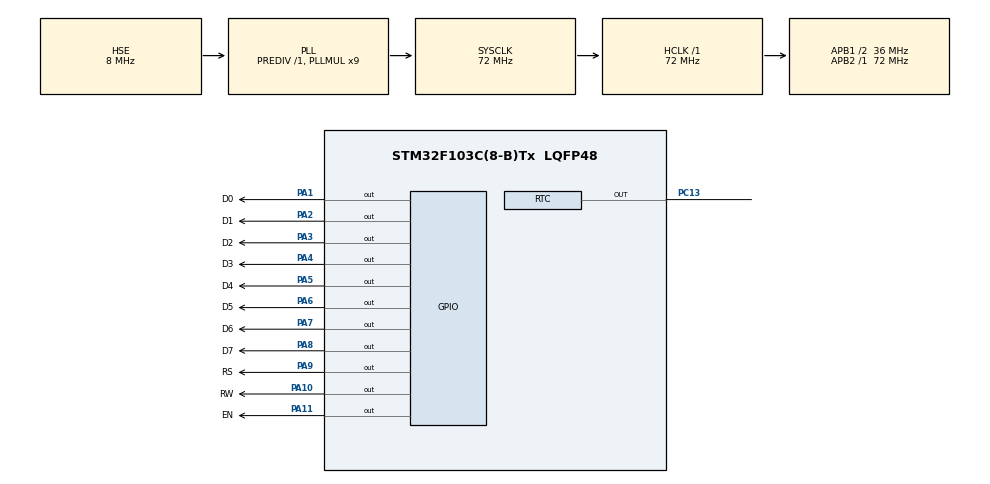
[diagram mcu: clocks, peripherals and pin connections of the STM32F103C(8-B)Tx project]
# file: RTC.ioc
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Mcu.Family=STM32F1
Mcu.Name=STM32F103C(8-B)Tx
Mcu.Package=LQFP48
NVIC.PriorityGroup=NVIC_PRIORITYGROUP_4
PA1.GPIO_Label=D0
PA1.GPIO_ModeDefaultOutputPP=GPIO_MODE_OUTPUT_PP
PA1.GPIO_Speed=GPIO_SPEED_FREQ_LOW
PA1.Signal=GPIO_Output
PA10.GPIO_Label=RW
PA10.GPIO_ModeDefaultOutputPP=GPIO_MODE_OUTPUT_PP
PA10.GPIO_Speed=GPIO_SPEED_FREQ_LOW
PA10.Signal=GPIO_Output
PA11.GPIO_Label=EN
PA11.GPIO_ModeDefaultOutputPP=GPIO_MODE_OUTPUT_PP
PA11.GPIO_Speed=GPIO_SPEED_FREQ_LOW
PA11.Signal=GPIO_Output
PA13.Signal=SYS_JTMS-SWDIO
PA14.Signal=SYS_JTCK-SWCLK
PA2.GPIO_Label=D1
PA2.GPIO_ModeDefaultOutputPP=GPIO_MODE_OUTPUT_PP
PA2.GPIO_Speed=GPIO_SPEED_FREQ_LOW
PA2.Signal=GPIO_Output
PA3.GPIO_Label=D2
PA3.GPIO_ModeDefaultOutputPP=GPIO_MODE_OUTPUT_PP
PA3.GPIO_Speed=GPIO_SPEED_FREQ_LOW
PA3.Signal=GPIO_Output
PA4.GPIO_Label=D3
PA4.GPIO_ModeDefaultOutputPP=GPIO_MODE_OUTPUT_PP
PA4.GPIO_Speed=GPIO_SPEED_FREQ_LOW
PA4.Signal=GPIO_Output
PA5.GPIO_Label=D4
PA5.GPIO_ModeDefaultOutputPP=GPIO_MODE_OUTPUT_PP
PA5.GPIO_Speed=GPIO_SPEED_FREQ_LOW
PA5.Signal=GPIO_Output
PA6.GPIO_Label=D5
PA6.GPIO_ModeDefaultOutputPP=GPIO_MODE_OUTPUT_PP
PA6.GPIO_Speed=GPIO_SPEED_FREQ_LOW
PA6.Signal=GPIO_Output
PA7.GPIO_Label=D6
PA7.GPIO_ModeDefaultOutputPP=GPIO_MODE_OUTPUT_PP
PA7.GPIO_Speed=GPIO_SPEED_FREQ_LOW
PA7.Signal=GPIO_Output
PA8.GPIO_Label=D7
PA8.GPIO_ModeDefaultOutputPP=GPIO_MODE_OUTPUT_PP
PA8.GPIO_Speed=GPIO_SPEED_FREQ_LOW
PA8.Signal=GPIO_Output
PA9.GPIO_Label=RS
PA9.GPIO_ModeDefaultOutputPP=GPIO_MODE_OUTPUT_PP
PA9.GPIO_Speed=GPIO_SPEED_FREQ_LOW
PA9.Signal=GPIO_Output
PC13-TAMPER-RTC.Mode=RTC OUT
PC13-TAMPER-RTC.Signal=RTC_OUT
PD0-OSC_IN.Mode=HSE-External-Oscillator
PD0-OSC_IN.Signal=RCC_OSC_IN
PD1-OSC_OUT.Mode=HSE-External-Oscillator
PD1-OSC_OUT.Signal=RCC_OSC_OUT
ProjectManager.HeapSize=0x200
ProjectManager.StackSize=0x400
ProjectManager.TargetToolchain=MDK-ARM V5
RCC.AHBFreq_Value=72000000
RCC.APB1CLKDivider=RCC_HCLK_DIV2
RCC.APB1Freq_Value=36000000
RCC.APB1TimFreq_Value=72000000
RCC.APB2Freq_Value=72000000
RCC.APB2TimFreq_Value=72000000
RCC.EnbaleCSS=true
RCC.HCLKFreq_Value=72000000
RCC.PLLMUL=RCC_PLL_MUL9
RCC.PLLSourceVirtual=RCC_PLLSOURCE_HSE
RCC.SYSCLKFreq_VALUE=72000000
RCC.SYSCLKSource=RCC_SYSCLKSOURCE_PLLCLK
RCC.USBFreq_Value=72000000
RTC.Date=21
RTC.Hours=2
RTC.Month=RTC_MONTH_SEPTEMBER
RTC.OutPut=RTC_OUTPUTSOURCE_SECOND
RTC.Year=20
VP_RTC_VS_RTC_Activate.Mode=RTC_Enabled
VP_RTC_VS_RTC_Calendar.Mode=RTC_Calendar
VP_SYS_VS_ND.Mode=No_Debug
board=custom

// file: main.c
/* USER CODE BEGIN Header */
/**
  ******************************************************************************
  * @file           : main.c
  * @brief          : Main program body
  ******************************************************************************
  * @attention
  *
  * <h2><center>&copy; Copyright (c) 2020 STMicroelectronics.
  * All rights reserved.</center></h2>
  *
  * This software component is licensed by ST under BSD 3-Clause license,
  * the "License"; You may not use this file except in compliance with the
  * License. You may obtain a copy of the License at:
  *                        opensource.org/licenses/BSD-3-Clause
  *
  ******************************************************************************
  */
/* USER CODE END Header */
#include "main.h"

/* USER CODE BEGIN Includes */
#include "lcd.h"
#include "stdio.h"
char text[16];
/* USER CODE END Includes */

RTC_HandleTypeDef hrtc;

/* USER CODE BEGIN PV */
RTC_TimeTypeDef time;
RTC_DateTypeDef date;
/* USER CODE END PV */

void SystemClock_Config(void);
static void MX_GPIO_Init(void);
static void MX_RTC_Init(void);

int main(void)
{

  /* MCU Configuration--------------------------------------------------------*/

  /* Reset of all peripherals, Initializes the Flash interface and the Systick. */
  HAL_Init();

  /* Configure the system clock */
  SystemClock_Config();

  /* Initialize all configured peripherals */
  MX_GPIO_Init();
  MX_RTC_Init();
  /* USER CODE BEGIN 2 */
	lcd_init();
  /* USER CODE END 2 */

  /* Infinite loop */
  /* USER CODE BEGIN WHILE */
  while (1)
  {
			HAL_RTC_GetTime(&hrtc,&time,RTC_FORMAT_BIN);
			HAL_RTC_GetDate(&hrtc,&date,RTC_FORMAT_BIN);

			sprintf(text,"    %2.2d:%2.2d:%2.2d    ",time.Hours,time.Minutes,time.Seconds);
			lcd_gotoxy(0,0);
			lcd_puts(text);
			sprintf(text,"   20%2.2d/%2.2d/%2.2d   ",date.Year,date.Month,date.Date);
			lcd_gotoxy(0,1);
			lcd_puts(text);
    /* USER CODE END WHILE */

  }
}

void SystemClock_Config(void)
{
  RCC_OscInitTypeDef RCC_OscInitStruct = {0};
  RCC_ClkInitTypeDef RCC_ClkInitStruct = {0};
  RCC_PeriphCLKInitTypeDef PeriphClkInit = {0};

  /** Initializes the RCC Oscillators according to the specified parameters
  * in the RCC_OscInitTypeDef structure.
  */
  RCC_OscInitStruct.OscillatorType = RCC_OSCILLATORTYPE_LSI|RCC_OSCILLATORTYPE_HSE;
  RCC_OscInitStruct.HSEState = RCC_HSE_ON;
  RCC_OscInitStruct.HSEPredivValue = RCC_HSE_PREDIV_DIV1;
  RCC_OscInitStruct.HSIState = RCC_HSI_ON;
  RCC_OscInitStruct.LSIState = RCC_LSI_ON;
  RCC_OscInitStruct.PLL.PLLState = RCC_PLL_ON;
  RCC_OscInitStruct.PLL.PLLSource = RCC_PLLSOURCE_HSE;
  RCC_OscInitStruct.PLL.PLLMUL = RCC_PLL_MUL9;
  if (HAL_RCC_OscConfig(&RCC_OscInitStruct) != HAL_OK)
  {
    Error_Handler();
  }
  /** Initializes the CPU, AHB and APB buses clocks
  */
  RCC_ClkInitStruct.ClockType = RCC_CLOCKTYPE_HCLK|RCC_CLOCKTYPE_SYSCLK
                              |RCC_CLOCKTYPE_PCLK1|RCC_CLOCKTYPE_PCLK2;
  RCC_ClkInitStruct.SYSCLKSource = RCC_SYSCLKSOURCE_PLLCLK;
  RCC_ClkInitStruct.AHBCLKDivider = RCC_SYSCLK_DIV1;
  RCC_ClkInitStruct.APB1CLKDivider = RCC_HCLK_DIV2;
  RCC_ClkInitStruct.APB2CLKDivider = RCC_HCLK_DIV1;

  if (HAL_RCC_ClockConfig(&RCC_ClkInitStruct, FLASH_LATENCY_2) != HAL_OK)
  {
    Error_Handler();
  }
  PeriphClkInit.PeriphClockSelection = RCC_PERIPHCLK_RTC;
  PeriphClkInit.RTCClockSelection = RCC_RTCCLKSOURCE_LSI;
  if (HAL_RCCEx_PeriphCLKConfig(&PeriphClkInit) != HAL_OK)
  {
    Error_Handler();
  }
  /** Enables the Clock Security System
  */
  HAL_RCC_EnableCSS();
}

static void MX_RTC_Init(void)
{

  RTC_TimeTypeDef sTime = {0};
  RTC_DateTypeDef DateToUpdate = {0};

  /** Initialize RTC Only
  */
  hrtc.Instance = RTC;
  hrtc.Init.AsynchPrediv = RTC_AUTO_1_SECOND;
  hrtc.Init.OutPut = RTC_OUTPUTSOURCE_SECOND;
  if (HAL_RTC_Init(&hrtc) != HAL_OK)
  {
    Error_Handler();
  }

  /** Initialize RTC and set the Time and Date
  */
  sTime.Hours = 0x2;
  sTime.Minutes = 0x0;
  sTime.Seconds = 0x0;

  if (HAL_RTC_SetTime(&hrtc, &sTime, RTC_FORMAT_BCD) != HAL_OK)
  {
    Error_Handler();
  }
  DateToUpdate.WeekDay = RTC_WEEKDAY_MONDAY;
  DateToUpdate.Month = RTC_MONTH_SEPTEMBER;
  DateToUpdate.Date = 0x21;
  DateToUpdate.Year = 0x20;

  if (HAL_RTC_SetDate(&hrtc, &DateToUpdate, RTC_FORMAT_BCD) != HAL_OK)
  {
    Error_Handler();
  }

}

static void MX_GPIO_Init(void)
{
  GPIO_InitTypeDef GPIO_InitStruct = {0};

  /* GPIO Ports Clock Enable */
  __HAL_RCC_GPIOC_CLK_ENABLE();
  __HAL_RCC_GPIOD_CLK_ENABLE();
  __HAL_RCC_GPIOA_CLK_ENABLE();

  /*Configure GPIO pin Output Level */
  HAL_GPIO_WritePin(GPIOA, D0_Pin|D1_Pin|D2_Pin|D3_Pin
                          |D4_Pin|D5_Pin|D6_Pin|D7_Pin
                          |RS_Pin|RW_Pin|EN_Pin, GPIO_PIN_RESET);

  /*Configure GPIO pins : D0_Pin D1_Pin D2_Pin D3_Pin
                           D4_Pin D5_Pin D6_Pin D7_Pin
                           RS_Pin RW_Pin EN_Pin */
  GPIO_InitStruct.Pin = D0_Pin|D1_Pin|D2_Pin|D3_Pin
                          |D4_Pin|D5_Pin|D6_Pin|D7_Pin
                          |RS_Pin|RW_Pin|EN_Pin;
  GPIO_InitStruct.Mode = GPIO_MODE_OUTPUT_PP;
  GPIO_InitStruct.Pull = GPIO_NOPULL;
  GPIO_InitStruct.Speed = GPIO_SPEED_FREQ_LOW;
  HAL_GPIO_Init(GPIOA, &GPIO_InitStruct);

}

void Error_Handler(void)
{
}

/************************ (C) COPYRIGHT STMicroelectronics *****END OF FILE****/
